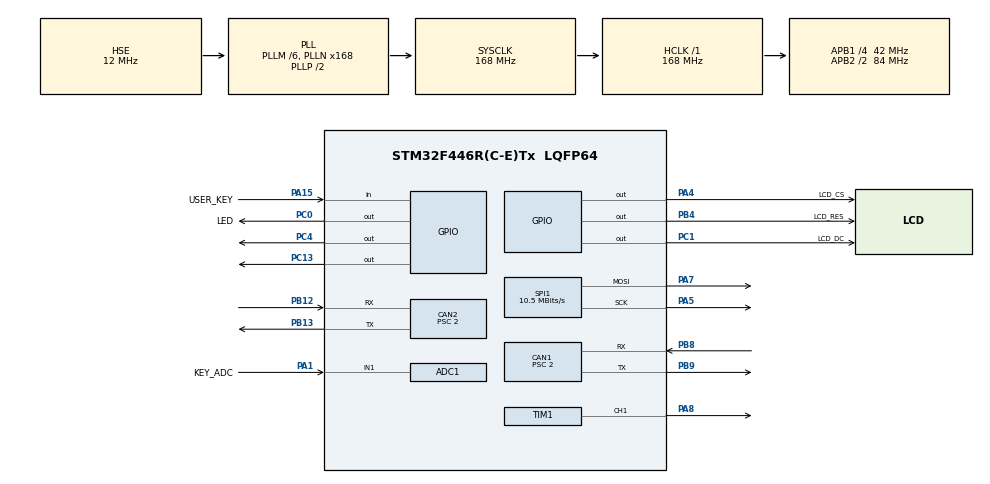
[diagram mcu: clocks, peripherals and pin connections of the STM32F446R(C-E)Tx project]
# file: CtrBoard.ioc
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ADC1.Channel-0\#ChannelRegularConversion=ADC_CHANNEL_1
ADC1.ContinuousConvMode=ENABLE
ADC1.DMAContinuousRequests=ENABLE
ADC1.NbrOfConversionFlag=1
ADC1.Rank-0\#ChannelRegularConversion=1
ADC1.SamplingTime-0\#ChannelRegularConversion=ADC_SAMPLETIME_56CYCLES
ADC1.master=1
CAN1.BS1=CAN_BS1_15TQ
CAN1.BS2=CAN_BS2_5TQ
CAN1.CalculateBaudRate=1000000
CAN1.CalculateTimeQuantum=47.61904761904762
CAN1.Prescaler=2
CAN2.BS1=CAN_BS1_15TQ
CAN2.BS2=CAN_BS2_5TQ
CAN2.CalculateBaudRate=1000000
CAN2.CalculateTimeBit=1000
CAN2.CalculateTimeQuantum=47.61904761904762
CAN2.Prescaler=2
Dma.ADC1.0.Direction=DMA_PERIPH_TO_MEMORY
Dma.ADC1.0.FIFOMode=DMA_FIFOMODE_DISABLE
Dma.ADC1.0.Instance=DMA2_Stream0
Dma.ADC1.0.MemDataAlignment=DMA_MDATAALIGN_HALFWORD
Dma.ADC1.0.MemInc=DMA_MINC_ENABLE
Dma.ADC1.0.Mode=DMA_CIRCULAR
Dma.ADC1.0.PeriphDataAlignment=DMA_PDATAALIGN_HALFWORD
Dma.ADC1.0.PeriphInc=DMA_PINC_DISABLE
Dma.ADC1.0.Priority=DMA_PRIORITY_LOW
Dma.Request0=ADC1
Mcu.Family=STM32F4
Mcu.Name=STM32F446R(C-E)Tx
Mcu.Package=LQFP64
NVIC.CAN1_RX0_IRQn=true\:0\:0\:false\:false\:true\:true\:true\:true
NVIC.CAN1_RX1_IRQn=true\:0\:0\:false\:false\:true\:true\:true\:true
NVIC.CAN2_RX0_IRQn=true\:0\:0\:false\:false\:true\:true\:true\:true
NVIC.CAN2_RX1_IRQn=true\:0\:0\:false\:false\:true\:true\:true\:true
NVIC.DMA2_Stream0_IRQn=true\:0\:0\:false\:false\:true\:false\:true\:true
NVIC.PriorityGroup=NVIC_PRIORITYGROUP_4
PA1.GPIO_Label=KEY_ADC
PA1.Signal=ADCx_IN1
PA13.Mode=Serial_Wire
PA13.Signal=SYS_JTMS-SWDIO
PA14.Mode=Serial_Wire
PA14.Signal=SYS_JTCK-SWCLK
PA15.GPIO_Label=USER_KEY
PA15.GPIO_PuPd=GPIO_PULLUP
PA15.Signal=GPIO_Input
PA4.GPIO_Label=LCD_CS
PA4.Signal=GPIO_Output
PA5.Mode=TX_Only_Simplex_Unidirect_Master
PA5.Signal=SPI1_SCK
PA7.Mode=TX_Only_Simplex_Unidirect_Master
PA7.Signal=SPI1_MOSI
PA8.Signal=S_TIM1_CH1
PB12.Mode=CAN_Activate
PB12.Signal=CAN2_RX
PB13.Mode=CAN_Activate
PB13.Signal=CAN2_TX
PB4.GPIO_Label=LCD_RES
PB4.Signal=GPIO_Output
PB8.Mode=CAN_Activate
PB8.Signal=CAN1_RX
PB9.Mode=CAN_Activate
PB9.Signal=CAN1_TX
PC0.GPIO_Label=LED
PC0.GPIO_ModeDefaultOutputPP=GPIO_MODE_OUTPUT_PP
PC0.GPIO_PuPd=GPIO_NOPULL
PC0.GPIO_Speed=GPIO_SPEED_FREQ_LOW
PC0.PinState=GPIO_PIN_RESET
PC0.Signal=GPIO_Output
PC1.GPIO_Label=LCD_DC
PC1.Signal=GPIO_Output
PC13.Signal=GPIO_Output
PC4.Signal=GPIO_Output
PH0-OSC_IN.Mode=HSE-External-Oscillator
PH0-OSC_IN.Signal=RCC_OSC_IN
PH1-OSC_OUT.Mode=HSE-External-Oscillator
PH1-OSC_OUT.Signal=RCC_OSC_OUT
ProjectManager.HeapSize=0x400
ProjectManager.StackSize=0x800
ProjectManager.TargetToolchain=MDK-ARM V5.27
RCC.AHBFreq_Value=168000000
RCC.APB1CLKDivider=RCC_HCLK_DIV4
RCC.APB1Freq_Value=42000000
RCC.APB1TimFreq_Value=84000000
RCC.APB2CLKDivider=RCC_HCLK_DIV2
RCC.APB2Freq_Value=84000000
RCC.APB2TimFreq_Value=168000000
RCC.CortexFreq_Value=168000000
RCC.HCLKFreq_Value=168000000
RCC.HSE_VALUE=12000000
RCC.PLLM=6
RCC.PLLN=168
RCC.PLLQ=7
RCC.PLLSAIM=6
RCC.PLLSAIN=96
RCC.PLLSAIP=RCC_PLLSAIP_DIV4
RCC.PLLSourceVirtual=RCC_PLLSOURCE_HSE
RCC.SYSCLKFreq_VALUE=168000000
RCC.SYSCLKSource=RCC_SYSCLKSOURCE_PLLCLK
RCC.USBFreq_Value=48000000
RCC.VCOOutputFreq_Value=336000000
SH.ADCx_IN1.0=ADC1_IN1,IN1
SH.S_TIM1_CH1.0=TIM1_CH1,PWM Generation1 CH1
SPI1.BaudRatePrescaler=SPI_BAUDRATEPRESCALER_8
SPI1.CLKPhase=SPI_PHASE_1EDGE
SPI1.CLKPolarity=SPI_POLARITY_HIGH
SPI1.CalculateBaudRate=10.5 MBits/s
SPI1.Direction=SPI_DIRECTION_2LINES
SPI1.Mode=SPI_MODE_MASTER
SPI1.VirtualType=VM_MASTER
TIM1.Channel-PWM\ Generation1\ CH1=TIM_CHANNEL_1
TIM1.Period=1000-1
board=custom

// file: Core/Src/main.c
/* USER CODE BEGIN Header */
/**
  ******************************************************************************
  * @file           : main.c
  * @brief          : Main program body
  ******************************************************************************
  * @attention
  *
  * <h2><center>&copy; Copyright (c) 2023 STMicroelectronics.
  * All rights reserved.</center></h2>
  *
  * This software component is licensed by ST under BSD 3-Clause license,
  * the "License"; You may not use this file except in compliance with the
  * License. You may obtain a copy of the License at:
  *                        opensource.org/licenses/BSD-3-Clause
  *
  ******************************************************************************
  */
/* USER CODE END Header */
#include "main.h"
#include "adc.h"
#include "can.h"
#include "dma.h"
#include "spi.h"
#include "tim.h"
#include "gpio.h"

/* USER CODE BEGIN Includes */
#include "can_driver.h"
#include "dm4310_ctrl.h"
#include "scheduler.h"
#include "mcu_config.h"
#include "drivers.h"
#include "adc_modlue.h"
#include "display.h"
/* USER CODE END Includes */

void SystemClock_Config(void);

int main(void)
{

  /* MCU Configuration--------------------------------------------------------*/

  /* Reset of all peripherals, Initializes the Flash interface and the Systick. */
  HAL_Init();

  /* Configure the system clock */
  SystemClock_Config();

  /* Initialize all configured peripherals */
  MX_GPIO_Init();
  MX_DMA_Init();
  MX_CAN1_Init();
  MX_CAN2_Init();
  MX_ADC1_Init();
  MX_SPI1_Init();
  MX_TIM1_Init();
  /* USER CODE BEGIN 2 */
	Power_OUT1_ON;
	Power_OUT2_ON;

	MCU_Init();

  /* USER CODE END 2 */

  /* Infinite loop */
  /* USER CODE BEGIN WHILE */
  while (1)
  {
//		scheduler_run();
    /* USER CODE END WHILE */

  }
}

void SystemClock_Config(void)
{
  RCC_OscInitTypeDef RCC_OscInitStruct = {0};
  RCC_ClkInitTypeDef RCC_ClkInitStruct = {0};

  /** Configure the main internal regulator output voltage
  */
  __HAL_RCC_PWR_CLK_ENABLE();
  __HAL_PWR_VOLTAGESCALING_CONFIG(PWR_REGULATOR_VOLTAGE_SCALE1);

  /** Initializes the RCC Oscillators according to the specified parameters
  * in the RCC_OscInitTypeDef structure.
  */
  RCC_OscInitStruct.OscillatorType = RCC_OSCILLATORTYPE_HSE;
  RCC_OscInitStruct.HSEState = RCC_HSE_ON;
  RCC_OscInitStruct.PLL.PLLState = RCC_PLL_ON;
  RCC_OscInitStruct.PLL.PLLSource = RCC_PLLSOURCE_HSE;
  RCC_OscInitStruct.PLL.PLLM = 6;
  RCC_OscInitStruct.PLL.PLLN = 168;
  RCC_OscInitStruct.PLL.PLLP = RCC_PLLP_DIV2;
  RCC_OscInitStruct.PLL.PLLQ = 7;
  RCC_OscInitStruct.PLL.PLLR = 2;
  if (HAL_RCC_OscConfig(&RCC_OscInitStruct) != HAL_OK)
  {
    Error_Handler();
  }

  /** Initializes the CPU, AHB and APB buses clocks
  */
  RCC_ClkInitStruct.ClockType = RCC_CLOCKTYPE_HCLK|RCC_CLOCKTYPE_SYSCLK
                              |RCC_CLOCKTYPE_PCLK1|RCC_CLOCKTYPE_PCLK2;
  RCC_ClkInitStruct.SYSCLKSource = RCC_SYSCLKSOURCE_PLLCLK;
  RCC_ClkInitStruct.AHBCLKDivider = RCC_SYSCLK_DIV1;
  RCC_ClkInitStruct.APB1CLKDivider = RCC_HCLK_DIV4;
  RCC_ClkInitStruct.APB2CLKDivider = RCC_HCLK_DIV2;

  if (HAL_RCC_ClockConfig(&RCC_ClkInitStruct, FLASH_LATENCY_5) != HAL_OK)
  {
    Error_Handler();
  }
}

void Error_Handler(void)
{
}
